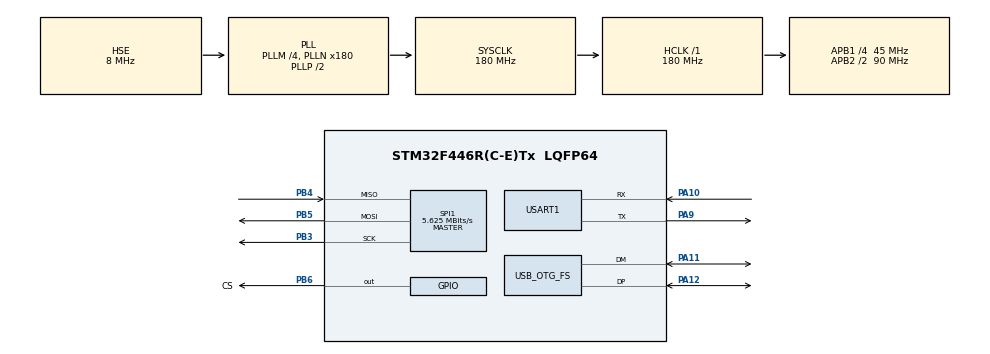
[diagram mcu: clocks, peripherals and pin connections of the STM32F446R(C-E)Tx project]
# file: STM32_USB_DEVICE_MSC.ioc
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Mcu.Family=STM32F4
Mcu.Name=STM32F446R(C-E)Tx
Mcu.Package=LQFP64
NVIC.OTG_FS_IRQn=true\:0\:0\:false\:false\:true\:false\:true\:true
NVIC.PriorityGroup=NVIC_PRIORITYGROUP_4
PA10.Mode=Asynchronous
PA10.Signal=USART1_RX
PA11.Mode=Device_Only
PA11.Signal=USB_OTG_FS_DM
PA12.Mode=Device_Only
PA12.Signal=USB_OTG_FS_DP
PA13.Mode=Serial_Wire
PA13.Signal=SYS_JTMS-SWDIO
PA14.Mode=Serial_Wire
PA14.Signal=SYS_JTCK-SWCLK
PA9.Mode=Asynchronous
PA9.Signal=USART1_TX
PB3.Mode=Full_Duplex_Master
PB3.Signal=SPI1_SCK
PB4.Mode=Full_Duplex_Master
PB4.Signal=SPI1_MISO
PB5.Mode=Full_Duplex_Master
PB5.Signal=SPI1_MOSI
PB6.GPIO_Label=CS
PB6.GPIO_Speed=GPIO_SPEED_FREQ_VERY_HIGH
PB6.PinState=GPIO_PIN_SET
PB6.Signal=GPIO_Output
PH0-OSC_IN.Mode=HSE-External-Oscillator
PH0-OSC_IN.Signal=RCC_OSC_IN
PH1-OSC_OUT.Mode=HSE-External-Oscillator
PH1-OSC_OUT.Signal=RCC_OSC_OUT
ProjectManager.HeapSize=0x200
ProjectManager.StackSize=0x400
ProjectManager.TargetToolchain=STM32CubeIDE
RCC.AHBFreq_Value=180000000
RCC.APB1CLKDivider=RCC_HCLK_DIV4
RCC.APB1Freq_Value=45000000
RCC.APB1TimFreq_Value=90000000
RCC.APB2CLKDivider=RCC_HCLK_DIV2
RCC.APB2Freq_Value=90000000
RCC.APB2TimFreq_Value=180000000
RCC.CortexFreq_Value=180000000
RCC.HCLKFreq_Value=180000000
RCC.HSE_VALUE=8000000
RCC.PLLM=4
RCC.PLLN=180
RCC.PLLSAIM=8
RCC.PLLSAIP=RCC_PLLSAIP_DIV4
RCC.PLLSourceVirtual=RCC_PLLSOURCE_HSE
RCC.SYSCLKFreq_VALUE=180000000
RCC.SYSCLKSource=RCC_SYSCLKSOURCE_PLLCLK
RCC.USBCLockSelection=RCC_CLK48CLKSOURCE_PLLSAIP
RCC.USBFreq_Value=48000000
RCC.VCOOutputFreq_Value=360000000
SPI1.BaudRatePrescaler=SPI_BAUDRATEPRESCALER_16
SPI1.CalculateBaudRate=5.625 MBits/s
SPI1.Direction=SPI_DIRECTION_2LINES
SPI1.Mode=SPI_MODE_MASTER
SPI1.VirtualType=VM_MASTER
USART1.VirtualMode=VM_ASYNC
USB_DEVICE.CLASS_NAME_FS=MSC
USB_DEVICE.MSC_MEDIA_PACKET-MSC_FS=4096
USB_DEVICE.VirtualMode-MSC_FS=Msc
USB_DEVICE.VirtualModeFS=Msc_FS
USB_OTG_FS.VirtualMode=Device_Only
VP_USB_DEVICE_VS_USB_DEVICE_MSC_FS.Mode=MSC_FS
board=custom

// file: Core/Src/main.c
/* USER CODE BEGIN Header */
/**
  ******************************************************************************
  * @file           : main.c
  * @brief          : Main program body
  ******************************************************************************
  * @attention
  *
  * Copyright (c) 2026 STMicroelectronics.
  * All rights reserved.
  *
  * This software is licensed under terms that can be found in the LICENSE file
  * in the root directory of this software component.
  * If no LICENSE file comes with this software, it is provided AS-IS.
  *
  ******************************************************************************
  */
/* USER CODE END Header */
#include "main.h"
#include "usb_device.h"

/* USER CODE BEGIN Includes */
#include "stdio.h"
#include "W25Qxx.h"
/* USER CODE END Includes */

SPI_HandleTypeDef hspi1;

UART_HandleTypeDef huart1;

void SystemClock_Config(void);
static void MX_GPIO_Init(void);
static void MX_USART1_UART_Init(void);
static void MX_SPI1_Init(void);

/* USER CODE BEGIN 0 */

int _write(int fd, unsigned char *buf, int len) {
  if (fd == 1 || fd == 2) {                     // stdout or stderr ?
    HAL_UART_Transmit(&huart1, buf, len, 999);  // Print to the UART
  }
  return len;
}

/* USER CODE END 0 */

int main(void)
{

  /* MCU Configuration--------------------------------------------------------*/

  /* Reset of all peripherals, Initializes the Flash interface and the Systick. */
  HAL_Init();

  /* Configure the system clock */
  SystemClock_Config();

  /* Initialize all configured peripherals */
  MX_GPIO_Init();
  MX_USART1_UART_Init();
  MX_USB_DEVICE_Init();
  MX_SPI1_Init();
  /* USER CODE BEGIN 2 */

//  uint8_t Tx[256];
//  uint8_t Rx[256];
//
//  for (int i=0;i <256; i++)
//  {
//	  Tx[i] = i;
//  }
//
//  memset (Rx, 0, 256);
//
//  uint32_t ID = W25Q_ReadID();
//  printf ("ID = 0x%08lX\r\n", ID);
//
//  W25Q_EraseSector(0);
//  W25Q_WriteBytes(0, Tx, 256);
//  W25Q_ReadBytes(0, Rx, 256);
//
//  if (memcmp (Tx, Rx, 256) == 0) printf ("Test Passed\r\n");
//  else printf ("Test Failed \r\n");

  /* USER CODE END 2 */

  /* Infinite loop */
  while (1)
  {

  }
}

void SystemClock_Config(void)
{
  RCC_OscInitTypeDef RCC_OscInitStruct = {0};
  RCC_ClkInitTypeDef RCC_ClkInitStruct = {0};

  /** Configure the main internal regulator output voltage
  */
  __HAL_RCC_PWR_CLK_ENABLE();
  __HAL_PWR_VOLTAGESCALING_CONFIG(PWR_REGULATOR_VOLTAGE_SCALE1);

  /** Initializes the RCC Oscillators according to the specified parameters
  * in the RCC_OscInitTypeDef structure.
  */
  RCC_OscInitStruct.OscillatorType = RCC_OSCILLATORTYPE_HSE;
  RCC_OscInitStruct.HSEState = RCC_HSE_ON;
  RCC_OscInitStruct.PLL.PLLState = RCC_PLL_ON;
  RCC_OscInitStruct.PLL.PLLSource = RCC_PLLSOURCE_HSE;
  RCC_OscInitStruct.PLL.PLLM = 4;
  RCC_OscInitStruct.PLL.PLLN = 180;
  RCC_OscInitStruct.PLL.PLLP = RCC_PLLP_DIV2;
  RCC_OscInitStruct.PLL.PLLQ = 2;
  RCC_OscInitStruct.PLL.PLLR = 2;
  if (HAL_RCC_OscConfig(&RCC_OscInitStruct) != HAL_OK)
  {
    Error_Handler();
  }

  /** Activate the Over-Drive mode
  */
  if (HAL_PWREx_EnableOverDrive() != HAL_OK)
  {
    Error_Handler();
  }

  /** Initializes the CPU, AHB and APB buses clocks
  */
  RCC_ClkInitStruct.ClockType = RCC_CLOCKTYPE_HCLK|RCC_CLOCKTYPE_SYSCLK
                              |RCC_CLOCKTYPE_PCLK1|RCC_CLOCKTYPE_PCLK2;
  RCC_ClkInitStruct.SYSCLKSource = RCC_SYSCLKSOURCE_PLLCLK;
  RCC_ClkInitStruct.AHBCLKDivider = RCC_SYSCLK_DIV1;
  RCC_ClkInitStruct.APB1CLKDivider = RCC_HCLK_DIV4;
  RCC_ClkInitStruct.APB2CLKDivider = RCC_HCLK_DIV2;

  if (HAL_RCC_ClockConfig(&RCC_ClkInitStruct, FLASH_LATENCY_5) != HAL_OK)
  {
    Error_Handler();
  }
}

static void MX_SPI1_Init(void)
{

  /* SPI1 parameter configuration*/
  hspi1.Instance = SPI1;
  hspi1.Init.Mode = SPI_MODE_MASTER;
  hspi1.Init.Direction = SPI_DIRECTION_2LINES;
  hspi1.Init.DataSize = SPI_DATASIZE_8BIT;
  hspi1.Init.CLKPolarity = SPI_POLARITY_LOW;
  hspi1.Init.CLKPhase = SPI_PHASE_1EDGE;
  hspi1.Init.NSS = SPI_NSS_SOFT;
  hspi1.Init.BaudRatePrescaler = SPI_BAUDRATEPRESCALER_16;
  hspi1.Init.FirstBit = SPI_FIRSTBIT_MSB;
  hspi1.Init.TIMode = SPI_TIMODE_DISABLE;
  hspi1.Init.CRCCalculation = SPI_CRCCALCULATION_DISABLE;
  hspi1.Init.CRCPolynomial = 10;
  if (HAL_SPI_Init(&hspi1) != HAL_OK)
  {
    Error_Handler();
  }

}

static void MX_USART1_UART_Init(void)
{

  huart1.Instance = USART1;
  huart1.Init.BaudRate = 115200;
  huart1.Init.WordLength = UART_WORDLENGTH_8B;
  huart1.Init.StopBits = UART_STOPBITS_1;
  huart1.Init.Parity = UART_PARITY_NONE;
  huart1.Init.Mode = UART_MODE_TX_RX;
  huart1.Init.HwFlowCtl = UART_HWCONTROL_NONE;
  huart1.Init.OverSampling = UART_OVERSAMPLING_16;
  if (HAL_UART_Init(&huart1) != HAL_OK)
  {
    Error_Handler();
  }

}

static void MX_GPIO_Init(void)
{
  GPIO_InitTypeDef GPIO_InitStruct = {0};

  /* GPIO Ports Clock Enable */
  __HAL_RCC_GPIOH_CLK_ENABLE();
  __HAL_RCC_GPIOA_CLK_ENABLE();
  __HAL_RCC_GPIOB_CLK_ENABLE();

  /*Configure GPIO pin Output Level */
  HAL_GPIO_WritePin(CS_GPIO_Port, CS_Pin, GPIO_PIN_SET);

  /*Configure GPIO pin : CS_Pin */
  GPIO_InitStruct.Pin = CS_Pin;
  GPIO_InitStruct.Mode = GPIO_MODE_OUTPUT_PP;
  GPIO_InitStruct.Pull = GPIO_NOPULL;
  GPIO_InitStruct.Speed = GPIO_SPEED_FREQ_VERY_HIGH;
  HAL_GPIO_Init(CS_GPIO_Port, &GPIO_InitStruct);

}

void Error_Handler(void)
{
  __disable_irq();
  while (1)
  {
  }
}
